# ESP32-S31 register map
Vendor: ESPRESSIF SYSTEMS (SHANGHAI) CO., LTD.; Series: ESP32 S-Series; File version: 1
CPU: RV32IMAFC r0p0, little endian, no MPU, FPU, 0 interrupt priority bits
Address unit: 32 bits
Registers are 32-bit, read-write, reset 0x0 unless marked. A register's access mark holds for its fields unless they carry their own. Offsets are from the block's base; [hi:lo] are bit positions.

## BITSCRAMBLER — BITSCRAMBLER Peripheral
Base 0x20356000
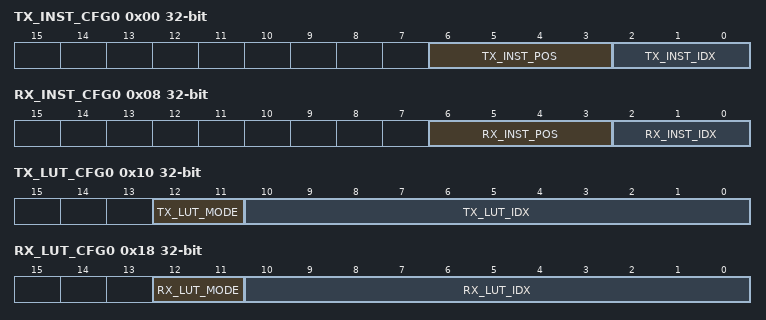
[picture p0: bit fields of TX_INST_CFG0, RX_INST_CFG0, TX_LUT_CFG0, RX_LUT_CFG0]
0x00 TX_INST_CFG0 — Control and configuration registers
  [6:3] TX_INST_POS — write this bits to specify the bit position of 257 bit instruction which in units of 32 bits
  [2:0] TX_INST_IDX — write this bits to specify the one of 8 instruction
0x04 TX_INST_CFG1 reset 0x4 — Control and configuration registers
  [31:0] TX_INST — write this bits to update instruction which specified by BITSCRAMBLER_TX_INST_CFG0_REG, Read this bits to get instruction which specified by BITSCRAMBLER_TX_INST_CFG0_REG
0x08 RX_INST_CFG0 — Control and configuration registers
  [6:3] RX_INST_POS — write this bits to specify the bit position of 257 bit instruction which in units of 32 bits
  [2:0] RX_INST_IDX — write this bits to specify the one of 8 instruction
0x0C RX_INST_CFG1 reset 0xC — Control and configuration registers
  [31:0] RX_INST — write this bits to update instruction which specified by BITSCRAMBLER_RX_INST_CFG0_REG, Read this bits to get instruction which specified by BITSCRAMBLER_RX_INST_CFG0_REG
0x10 TX_LUT_CFG0 — Control and configuration registers
  [12:11] TX_LUT_MODE — write this bits to specify the bytes mode of LUT RAM, 0: 1 byte,1: 2bytes, 2: 4 bytes
  [10:0] TX_LUT_IDX — write this bits to specify the bytes position of LUT RAM based on reg_bitscrambler_tx_lut_mode
0x14 TX_LUT_CFG1 reset 0x14 — Control and configuration registers
  [31:0] TX_LUT — write this bits to update LUT which specified by BITSCRAMBLER_TX_LUT_CFG0_REG, Read this bits to get LUT which specified by BITSCRAMBLER_TX_LUT_CFG0_REG
0x18 RX_LUT_CFG0 — Control and configuration registers
  [12:11] RX_LUT_MODE — write this bits to specify the bytes mode of LUT RAM, 0: 1 byte,1: 2bytes, 2: 4 bytes
  [10:0] RX_LUT_IDX — write this bits to specify the bytes position of LUT RAM based on reg_bitscrambler_rx_lut_mode
0x1C RX_LUT_CFG1 reset 0x1C — Control and configuration registers
  [31:0] RX_LUT — write this bits to update LUT which specified by BITSCRAMBLER_RX_LUT_CFG0_REG, Read this bits to get LUT which specified by BITSCRAMBLER_RX_LUT_CFG0_REG
0x20 TX_TAILING_BITS — Control and configuration registers
  [15:0] TX_TAILING_BITS — write this bits to specify the extra data bit length after getting EOF
0x24 RX_TAILING_BITS — Control and configuration registers
  [15:0] RX_TAILING_BITS — write this bits to specify the extra data bit length after getting EOF
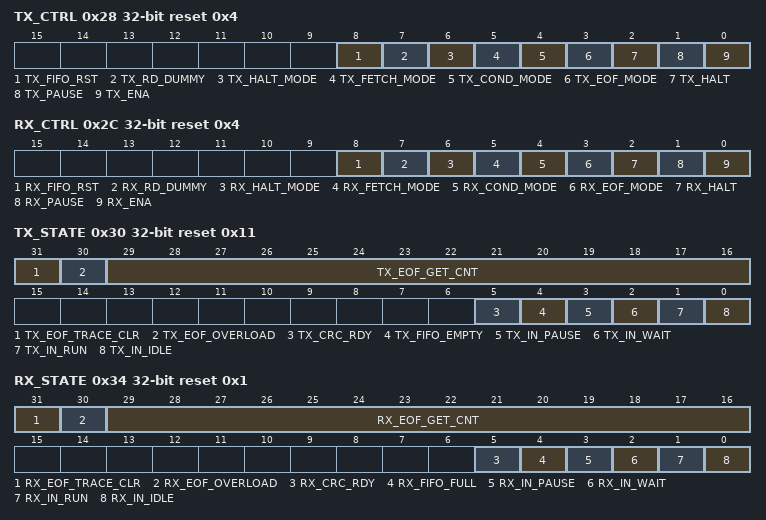
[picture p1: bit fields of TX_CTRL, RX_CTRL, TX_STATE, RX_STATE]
0x28 TX_CTRL access per field reset 0x4 — Control and configuration registers
  [8] TX_FIFO_RST wo — write this bit to reset the bitscrambler tx fifo
  [7] TX_RD_DUMMY rw — write this bit to set the bitscrambler tx core read data mode when EOF received.0: wait read data, 1: ignore read data
  [6] TX_HALT_MODE rw — write this bit to set the bitscrambler tx core halt mode when tx_halt is set, 0: wait write data back done, , 1: ignore write data back
  [5] TX_FETCH_MODE rw — write this bit to set the bitscrambler tx core fetch instruction mode, 0: prefetch by reset, 1: fetch by instrutions
  [4] TX_COND_MODE rw — write this bit to specify the LOOP instruction condition mode of bitscrambler tx core, 0: use the little than operator to get the condition, 1: use not equal operator to get the condition
  [3] TX_EOF_MODE rw — write this bit to ser the bitscrambler tx core EOF signal generating mode which is combined with reg_bitscrambler_tx_tailing_bits, 0: counter by read dma fifo, 0 counter by write peripheral buffer
  [2] TX_HALT rw — write this bit to halt the bitscrambler tx core
  [1] TX_PAUSE rw — write this bit to pause the bitscrambler tx core
  [0] TX_ENA rw — write this bit to enable the bitscrambler tx
0x2C RX_CTRL access per field reset 0x4 — Control and configuration registers
  [8] RX_FIFO_RST wo — write this bit to reset the bitscrambler rx fifo
  [7] RX_RD_DUMMY rw — write this bit to set the bitscrambler rx core read data mode when EOF received.0: wait read data, 1: ignore read data
  [6] RX_HALT_MODE rw — write this bit to set the bitscrambler rx core halt mode when rx_halt is set, 0: wait write data back done, , 1: ignore write data back
  [5] RX_FETCH_MODE rw — write this bit to set the bitscrambler rx core fetch instruction mode, 0: prefetch by reset, 1: fetch by instrutions
  [4] RX_COND_MODE rw — write this bit to specify the LOOP instruction condition mode of bitscrambler rx core, 0: use the little than operator to get the condition, 1: use not equal operator to get the condition
  [3] RX_EOF_MODE rw — write this bit to ser the bitscrambler rx core EOF signal generating mode which is combined with reg_bitscrambler_rx_tailing_bits, 0: counter by read peripheral buffer, 0 counter by write dma fifo
  [2] RX_HALT rw — write this bit to halt the bitscrambler rx core
  [1] RX_PAUSE rw — write this bit to pause the bitscrambler rx core
  [0] RX_ENA rw — write this bit to enable the bitscrambler rx
0x30 TX_STATE access per field reset 0x11 — Status registers
  [31] TX_EOF_TRACE_CLR wo — write this bit to clear reg_bitscrambler_tx_eof_overload and reg_bitscrambler_tx_eof_get_cnt registers
  [30] TX_EOF_OVERLOAD ro — represents the some EOFs will be lost for bitscrambler tx core
  [29:16] TX_EOF_GET_CNT ro — represents the bytes numbers of bitscrambler tx core when get EOF
  [5] TX_CRC_RDY ro — represents the crc calculate result of bitscrambler tx path is ready
  [4] TX_FIFO_EMPTY ro — represents the bitscrambler tx fifo in empty state
  [3] TX_IN_PAUSE ro — represents the bitscrambler tx core in pause mode
  [2] TX_IN_WAIT ro — represents the bitscrambler tx core in wait mode to wait write back done
  [1] TX_IN_RUN ro — represents the bitscrambler tx core in run mode
  [0] TX_IN_IDLE ro — represents the bitscrambler tx core in halt mode
0x34 RX_STATE access per field reset 0x1 — Status registers
  [31] RX_EOF_TRACE_CLR wo — write this bit to clear reg_bitscrambler_rx_eof_overload and reg_bitscrambler_rx_eof_get_cnt registers
  [30] RX_EOF_OVERLOAD ro — represents the some EOFs will be lost for bitscrambler rx core
  [29:16] RX_EOF_GET_CNT ro — represents the bytes numbers of bitscrambler rx core when get EOF
  [5] RX_CRC_RDY ro — represents the crc calculate result of bitscrambler rx path is ready
  [4] RX_FIFO_FULL ro — represents the bitscrambler rx fifo in full state
  [3] RX_IN_PAUSE ro — represents the bitscrambler rx core in pause mode
  [2] RX_IN_WAIT ro — represents the bitscrambler rx core in wait mode to wait write back done
  [1] RX_IN_RUN ro — represents the bitscrambler rx core in run mode
  [0] RX_IN_IDLE ro — represents the bitscrambler rx core in halt mode
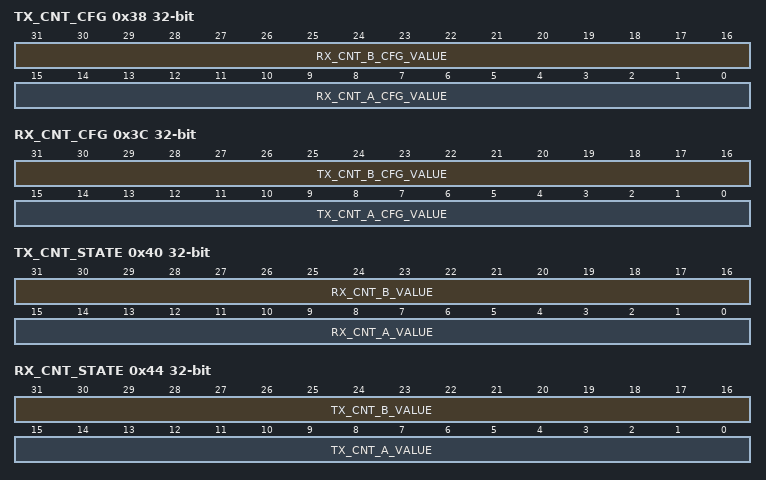
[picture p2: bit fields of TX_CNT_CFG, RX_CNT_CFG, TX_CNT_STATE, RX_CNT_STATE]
0x38 TX_CNT_CFG — TX Counter cfg registers
  [31:16] RX_CNT_B_CFG_VALUE — config the tx counter b value
  [15:0] RX_CNT_A_CFG_VALUE — config the tx counter a value
0x3C RX_CNT_CFG — RX Counter cfg registers
  [31:16] TX_CNT_B_CFG_VALUE — config the rx counter b value
  [15:0] TX_CNT_A_CFG_VALUE — config the rx counter a value
0x40 TX_CNT_STATE ro — TX Counter state registers
  [31:16] RX_CNT_B_VALUE — read the tx counter b value
  [15:0] RX_CNT_A_VALUE — read the tx counter a value
0x44 RX_CNT_STATE ro — RX Counter state registers
  [31:16] TX_CNT_B_VALUE — read the rx counter b value
  [15:0] TX_CNT_A_VALUE — read the rx counter a value
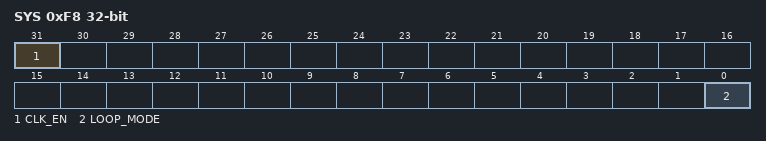
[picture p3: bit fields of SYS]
0xF8 SYS — Control and configuration registers
  [31] CLK_EN — Write this bit to enable the configuration register clock to be always-on. 0: turn on during access, 1: always-on.
  [0] LOOP_MODE — write this bit to set the bitscrambler tx loop back to DMA rx
0xFC VERSION reset 0x2501170 — Control and configuration registers
  [27:0] BITSCRAMBLER_VER — Reserved
